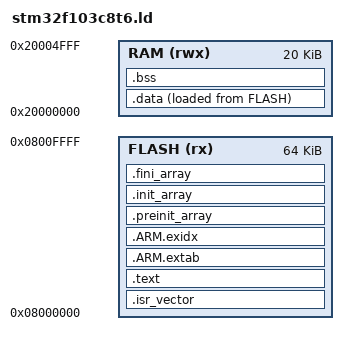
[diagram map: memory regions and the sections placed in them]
/*
 * libestdx: STM32F103C8T6 链接脚本 —— 64K FLASH / 20K SRAM
 *
 * 启动文件 startup_stm32f103xb.s 需要的符号:
 *   _estack(栈顶) _sidata(data 的装载地址) _sdata/_edata _sbss/_ebss
 *
 * 注:C8T6 名义 64K flash。民间实测后 64K 一般也能写,但别依赖,
 *     镜像超 64K 让链接器在这里报错,总好过烧录时默默翻车。
 */
ENTRY(Reset_Handler)

MEMORY
{
    FLASH (rx)  : ORIGIN = 0x08000000, LENGTH = 64K
    RAM   (rwx) : ORIGIN = 0x20000000, LENGTH = 20K
}

_estack = ORIGIN(RAM) + LENGTH(RAM);

SECTIONS
{
    .isr_vector :
    {
        KEEP(*(.isr_vector))
    } > FLASH

    .text :
    {
        *(.text*)
        *(.rodata*)
        KEEP(*(.init))
        KEEP(*(.fini))
        . = ALIGN(4);
        _etext = .;
    } > FLASH

    .ARM.extab : { *(.ARM.extab*) } > FLASH
    .ARM.exidx :
    {
        __exidx_start = .;
        *(.ARM.exidx*)
        __exidx_end = .;
    } > FLASH

    /* C++ 全局构造:必须 KEEP,否则 --gc-sections 会裁掉 */
    .preinit_array :
    {
        PROVIDE_HIDDEN(__preinit_array_start = .);
        KEEP(*(.preinit_array*))
        PROVIDE_HIDDEN(__preinit_array_end = .);
    } > FLASH
    .init_array :
    {
        PROVIDE_HIDDEN(__init_array_start = .);
        KEEP(*(SORT(.init_array.*)))
        KEEP(*(.init_array*))
        PROVIDE_HIDDEN(__init_array_end = .);
    } > FLASH
    .fini_array :
    {
        PROVIDE_HIDDEN(__fini_array_start = .);
        KEEP(*(SORT(.fini_array.*)))
        KEEP(*(.fini_array*))
        PROVIDE_HIDDEN(__fini_array_end = .);
    } > FLASH

    /* 运行在 RAM、存储在 FLASH 的数据;_sidata = 装载地址(FLASH 里那份) */
    _sidata = LOADADDR(.data);
    .data :
    {
        . = ALIGN(4);
        _sdata = .;
        *(.data*)
        . = ALIGN(4);
        _edata = .;
    } > RAM AT > FLASH

    .bss (NOLOAD) :
    {
        . = ALIGN(4);
        _sbss = .;
        *(.bss*)
        *(COMMON)
        . = ALIGN(4);
        _ebss = .;
    } > RAM

    . = ALIGN(4);
    _end = .;   /* 堆从此向上,栈从 _estack 向下 */
}
